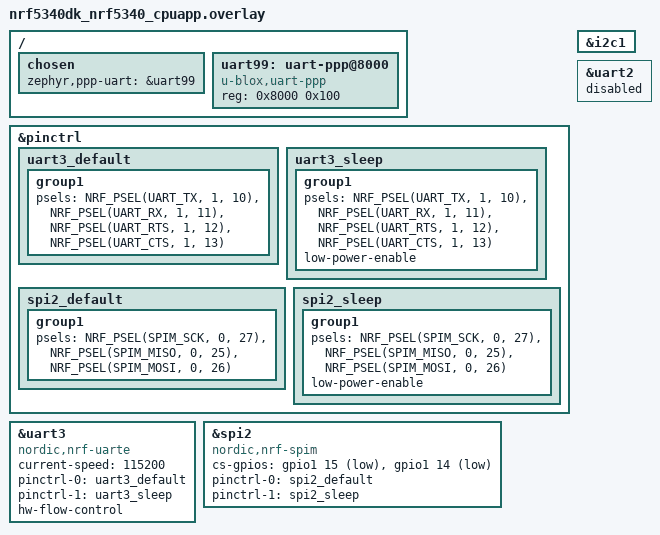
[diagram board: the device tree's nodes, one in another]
&pinctrl {
	uart3_default: uart3_default {
		group1 {
			psels = <NRF_PSEL(UART_TX, 1, 10)>,
                <NRF_PSEL(UART_RX, 1, 11)>,
				<NRF_PSEL(UART_RTS, 1, 12)>,
				<NRF_PSEL(UART_CTS, 1, 13)>;
		};
	};

	uart3_sleep: uart3_sleep {
		group1 {
			psels = <NRF_PSEL(UART_TX, 1, 10)>,
				<NRF_PSEL(UART_RX, 1, 11)>,
				<NRF_PSEL(UART_RTS, 1, 12)>,
				<NRF_PSEL(UART_CTS, 1, 13)>;
			low-power-enable;
		};
	};

    spi2_default: spi2_default {
        group1 {
            psels = <NRF_PSEL(SPIM_SCK, 0, 27)>,
                    <NRF_PSEL(SPIM_MISO, 0, 25)>,
                    <NRF_PSEL(SPIM_MOSI, 0, 26)>;
        };
    };

    spi2_sleep: spi2_sleep {
        group1 {
            psels = <NRF_PSEL(SPIM_SCK, 0, 27)>,
                    <NRF_PSEL(SPIM_MISO, 0, 25)>,
                    <NRF_PSEL(SPIM_MOSI, 0, 26)>;
            low-power-enable;
        };
    };

};

&i2c1 {
    status = "okay";
    /* Otherwise board default settings are good. */
};

&uart2 {
    /* Disable UART2 so that we can use SPI2 */
    status = "disabled";
};

/* This used to be on 2 but we need to put the SPI there so it has moved to 3. */
&uart3 {
    compatible = "nordic,nrf-uarte";
    current-speed = <115200>;
    status = "okay";
    pinctrl-0 = <&uart3_default>;
    pinctrl-1 = <&uart3_sleep>;
    pinctrl-names = "default", "sleep";
    hw-flow-control;
};

/* Can't use the default SPI pins as they overlap with the flow control pins we use for the UART.
   Note that we set gpio1 15 below as well as the real gpio1 14 simply to test the CS selection
   logic */
&spi2 {
    compatible = "nordic,nrf-spim";
    status = "okay";
    cs-gpios = <&gpio1 15 GPIO_ACTIVE_LOW>,
               <&gpio1 14 GPIO_ACTIVE_LOW>;
    pinctrl-0 = <&spi2_default>;
    pinctrl-1 = <&spi2_sleep>;
    pinctrl-names = "default", "sleep";
};

/* Required for PPP-level integration with ubxlib to work */
/ { // The leading / indicates that we're in the root section
    // This chooses uart instance 99 to be the zephyr,ppp-uart that ppp.c wants
    chosen {
        zephyr,ppp-uart = &uart99;
    };

    // This creates instance 99 of a uart that we will give to zephyr,ppp-uart
    uart99: uart-ppp@8000 { // The "8000" here is irrelevant but required for Zephyr to work
        compatible = "u-blox,uart-ppp"; // The important part: this is an instance of u-blox,uart-ppp
        reg = <0x8000 0x100>; // This is irrelevant but required for Zephyr to work
        status = "okay"; // Zephyr boiler-plate
    };
};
